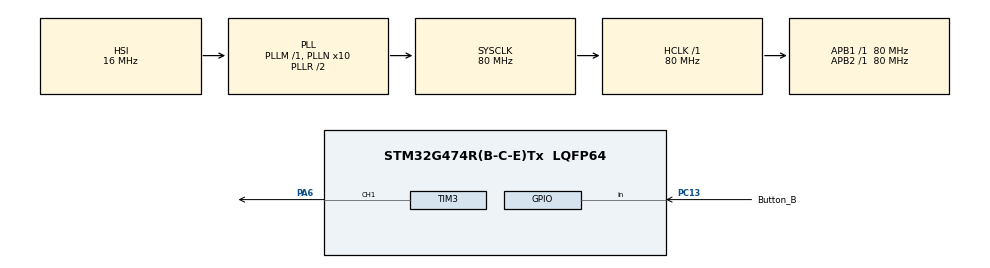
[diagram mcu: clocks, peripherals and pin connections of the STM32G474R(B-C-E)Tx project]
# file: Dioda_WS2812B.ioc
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Dma.Request0=TIM3_CH1
Dma.TIM3_CH1.0.Direction=DMA_MEMORY_TO_PERIPH
Dma.TIM3_CH1.0.EventEnable=DISABLE
Dma.TIM3_CH1.0.Instance=DMA1_Channel6
Dma.TIM3_CH1.0.MemDataAlignment=DMA_MDATAALIGN_BYTE
Dma.TIM3_CH1.0.MemInc=DMA_MINC_ENABLE
Dma.TIM3_CH1.0.Mode=DMA_NORMAL
Dma.TIM3_CH1.0.PeriphDataAlignment=DMA_PDATAALIGN_HALFWORD
Dma.TIM3_CH1.0.PeriphInc=DMA_PINC_DISABLE
Dma.TIM3_CH1.0.Polarity=HAL_DMAMUX_REQ_GEN_RISING
Dma.TIM3_CH1.0.Priority=DMA_PRIORITY_LOW
Dma.TIM3_CH1.0.RequestNumber=1
Dma.TIM3_CH1.0.SignalID=NONE
Dma.TIM3_CH1.0.SyncEnable=DISABLE
Dma.TIM3_CH1.0.SyncPolarity=HAL_DMAMUX_SYNC_NO_EVENT
Dma.TIM3_CH1.0.SyncRequestNumber=1
Dma.TIM3_CH1.0.SyncSignalID=NONE
Mcu.Family=STM32G4
Mcu.Name=STM32G474R(B-C-E)Tx
Mcu.Package=LQFP64
NVIC.DMA1_Channel6_IRQn=true\:0\:0\:false\:false\:true\:false\:true\:true
NVIC.PriorityGroup=NVIC_PRIORITYGROUP_4
PA13.Mode=Serial_Wire
PA13.Signal=SYS_JTMS-SWDIO
PA14.Mode=Serial_Wire
PA14.Signal=SYS_JTCK-SWCLK
PA6.Signal=S_TIM3_CH1
PC13.GPIO_Label=Button_B
PC13.Signal=GPIO_Input
ProjectManager.HeapSize=0x200
ProjectManager.StackSize=0x400
ProjectManager.TargetToolchain=STM32CubeIDE
RCC.ADC12Freq_Value=80000000
RCC.ADC345Freq_Value=80000000
RCC.AHBFreq_Value=80000000
RCC.APB1Freq_Value=80000000
RCC.APB1TimFreq_Value=80000000
RCC.APB2Freq_Value=80000000
RCC.APB2TimFreq_Value=80000000
RCC.CortexFreq_Value=80000000
RCC.EXTERNAL_CLOCK_VALUE=12288000
RCC.HCLKFreq_Value=80000000
RCC.HSE_VALUE=8000000
RCC.HSI48_VALUE=48000000
RCC.HSI_VALUE=16000000
RCC.LSE_VALUE=32768
RCC.PLLN=10
RCC.SYSCLKFreq_VALUE=80000000
RCC.SYSCLKSource=RCC_SYSCLKSOURCE_PLLCLK
RCC.USBFreq_Value=80000000
RCC.VCOOutputFreq_Value=160000000
SH.S_TIM3_CH1.0=TIM3_CH1,PWM Generation1 CH1
TIM3.Channel-PWM\ Generation1\ CH1=TIM_CHANNEL_1
TIM3.PeriodNoDither=99
VP_SYS_VS_DBSignals.Mode=DisableDeadBatterySignals
VP_TIM3_VS_ClockSourceINT.Mode=Internal
board=custom

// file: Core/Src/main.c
/* USER CODE BEGIN Header */
/**
  ******************************************************************************
  * @file           : main.c
  * @brief          : Main program body
  ******************************************************************************
  * @attention
  *
  * Copyright (c) 2026 STMicroelectronics.
  * All rights reserved.
  *
  * This software is licensed under terms that can be found in the LICENSE file
  * in the root directory of this software component.
  * If no LICENSE file comes with this software, it is provided AS-IS.
  *
  ******************************************************************************
  */
/* USER CODE END Header */
#include "main.h"

/* USER CODE BEGIN Includes */
#include "ws2812b.h"
#include <stdlib.h>
/* USER CODE END Includes */

TIM_HandleTypeDef htim3;
DMA_HandleTypeDef hdma_tim3_ch1;

void SystemClock_Config(void);
static void MX_GPIO_Init(void);
static void MX_DMA_Init(void);
static void MX_TIM3_Init(void);

int main(void)
{

  /* MCU Configuration--------------------------------------------------------*/

  /* Reset of all peripherals, Initializes the Flash interface and the Systick. */
  HAL_Init();

  /* Configure the system clock */
  SystemClock_Config();

  /* Initialize all configured peripherals */
  MX_GPIO_Init();
  MX_DMA_Init();
  MX_TIM3_Init();
  /* USER CODE BEGIN 2 */
  uint32_t last_ms = HAL_GetTick(); //odczytanie aktualnego czasu
  uint32_t last_ms_blue = last_ms;
  ws2812b_init();
  //ustawienie zmiennych odpowiadajacych za kolory
  uint8_t red = 255;
  uint8_t green = 0;
  uint8_t blue = 0;
  uint8_t blue_count = 0;
  uint8_t blue_state = 0;
  /* USER CODE END 2 */

  /* Infinite loop */
  while (1)
  {

    /* USER CODE BEGIN 3 */
	  uint32_t now = HAL_GetTick();

	  if ((now-last_ms)>=3000)
		  last_ms = now;

	  uint32_t t = now - last_ms;

	  // realizacja sygnału prostokątnego z wypełnieniem 50% - 0-1500ms - dioda red świeci, 1500-3000ms nie świeci
	  red = (t<1500) ? 255:0;

	  // realizacja sygnału piłokształtnego - natężenie diody ciągle rośnie aż do wyzerowania t gdzie przyjmuje wartości zbliżone do zera
	  green = t*255/3000;

	  // odczytanie naciśniecia przycisku oraz zapobieganie ponownemu kliknieciu przed zakonczeniem cyklu
	  if (HAL_GPIO_ReadPin(Button_B_GPIO_Port, Button_B_Pin) == GPIO_PIN_RESET && blue_count == 0){
		  blue_count = 6;
	  	  blue_state = 1;
	  	  last_ms_blue = now;
	  }
	  // sekwencja 6 cykli 255->0->255->0->255->0 realizująca miganie
	  if (blue_count !=0 && now - last_ms_blue >= 250 ){
		  if (blue_state == 1)
			  blue = 255;
		  else
			  blue = 0;
		  blue_state=!blue_state;
		  last_ms_blue = now;
		  blue_count --;
  	  }
	  // w razie czego żeby blue napewno zgasł chociaż w 6 cyklach powinien zgasnac i tak
	  if (blue_count == 0) {
	      blue = 0;
	  }

	  // ustawienie kolorow do bufforu kazdego leda
	  for (int led_n = 0; led_n<LED_N; led_n++){
		  ws2812b_set_color(led_n, green, red, blue);
	  }

	  ws2812b_update();
  }
  /* USER CODE END 3 */
}

void SystemClock_Config(void)
{
  RCC_OscInitTypeDef RCC_OscInitStruct = {0};
  RCC_ClkInitTypeDef RCC_ClkInitStruct = {0};

  /** Configure the main internal regulator output voltage
  */
  HAL_PWREx_ControlVoltageScaling(PWR_REGULATOR_VOLTAGE_SCALE1);

  /** Initializes the RCC Oscillators according to the specified parameters
  * in the RCC_OscInitTypeDef structure.
  */
  RCC_OscInitStruct.OscillatorType = RCC_OSCILLATORTYPE_HSI;
  RCC_OscInitStruct.HSIState = RCC_HSI_ON;
  RCC_OscInitStruct.HSICalibrationValue = RCC_HSICALIBRATION_DEFAULT;
  RCC_OscInitStruct.PLL.PLLState = RCC_PLL_ON;
  RCC_OscInitStruct.PLL.PLLSource = RCC_PLLSOURCE_HSI;
  RCC_OscInitStruct.PLL.PLLM = RCC_PLLM_DIV1;
  RCC_OscInitStruct.PLL.PLLN = 10;
  RCC_OscInitStruct.PLL.PLLP = RCC_PLLP_DIV2;
  RCC_OscInitStruct.PLL.PLLQ = RCC_PLLQ_DIV2;
  RCC_OscInitStruct.PLL.PLLR = RCC_PLLR_DIV2;
  if (HAL_RCC_OscConfig(&RCC_OscInitStruct) != HAL_OK)
  {
    Error_Handler();
  }

  /** Initializes the CPU, AHB and APB buses clocks
  */
  RCC_ClkInitStruct.ClockType = RCC_CLOCKTYPE_HCLK|RCC_CLOCKTYPE_SYSCLK
                              |RCC_CLOCKTYPE_PCLK1|RCC_CLOCKTYPE_PCLK2;
  RCC_ClkInitStruct.SYSCLKSource = RCC_SYSCLKSOURCE_PLLCLK;
  RCC_ClkInitStruct.AHBCLKDivider = RCC_SYSCLK_DIV1;
  RCC_ClkInitStruct.APB1CLKDivider = RCC_HCLK_DIV1;
  RCC_ClkInitStruct.APB2CLKDivider = RCC_HCLK_DIV1;

  if (HAL_RCC_ClockConfig(&RCC_ClkInitStruct, FLASH_LATENCY_2) != HAL_OK)
  {
    Error_Handler();
  }
}

static void MX_TIM3_Init(void)
{

  TIM_ClockConfigTypeDef sClockSourceConfig = {0};
  TIM_MasterConfigTypeDef sMasterConfig = {0};
  TIM_OC_InitTypeDef sConfigOC = {0};

  htim3.Instance = TIM3;
  htim3.Init.Prescaler = 0;
  htim3.Init.CounterMode = TIM_COUNTERMODE_UP;
  htim3.Init.Period = 99;
  htim3.Init.ClockDivision = TIM_CLOCKDIVISION_DIV1;
  htim3.Init.AutoReloadPreload = TIM_AUTORELOAD_PRELOAD_DISABLE;
  if (HAL_TIM_Base_Init(&htim3) != HAL_OK)
  {
    Error_Handler();
  }
  sClockSourceConfig.ClockSource = TIM_CLOCKSOURCE_INTERNAL;
  if (HAL_TIM_ConfigClockSource(&htim3, &sClockSourceConfig) != HAL_OK)
  {
    Error_Handler();
  }
  if (HAL_TIM_PWM_Init(&htim3) != HAL_OK)
  {
    Error_Handler();
  }
  sMasterConfig.MasterOutputTrigger = TIM_TRGO_RESET;
  sMasterConfig.MasterSlaveMode = TIM_MASTERSLAVEMODE_DISABLE;
  if (HAL_TIMEx_MasterConfigSynchronization(&htim3, &sMasterConfig) != HAL_OK)
  {
    Error_Handler();
  }
  sConfigOC.OCMode = TIM_OCMODE_PWM1;
  sConfigOC.Pulse = 0;
  sConfigOC.OCPolarity = TIM_OCPOLARITY_HIGH;
  sConfigOC.OCFastMode = TIM_OCFAST_DISABLE;
  if (HAL_TIM_PWM_ConfigChannel(&htim3, &sConfigOC, TIM_CHANNEL_1) != HAL_OK)
  {
    Error_Handler();
  }
  HAL_TIM_MspPostInit(&htim3);

}

static void MX_DMA_Init(void)
{

  /* DMA controller clock enable */
  __HAL_RCC_DMAMUX1_CLK_ENABLE();
  __HAL_RCC_DMA1_CLK_ENABLE();

  /* DMA interrupt init */
  /* DMA1_Channel6_IRQn interrupt configuration */
  HAL_NVIC_SetPriority(DMA1_Channel6_IRQn, 0, 0);
  HAL_NVIC_EnableIRQ(DMA1_Channel6_IRQn);

}

static void MX_GPIO_Init(void)
{
  GPIO_InitTypeDef GPIO_InitStruct = {0};

  /* GPIO Ports Clock Enable */
  __HAL_RCC_GPIOC_CLK_ENABLE();
  __HAL_RCC_GPIOA_CLK_ENABLE();

  /*Configure GPIO pin : Button_B_Pin */
  GPIO_InitStruct.Pin = Button_B_Pin;
  GPIO_InitStruct.Mode = GPIO_MODE_INPUT;
  GPIO_InitStruct.Pull = GPIO_NOPULL;
  HAL_GPIO_Init(Button_B_GPIO_Port, &GPIO_InitStruct);

}

void Error_Handler(void)
{
  __disable_irq();
  while (1)
  {
  }
}
